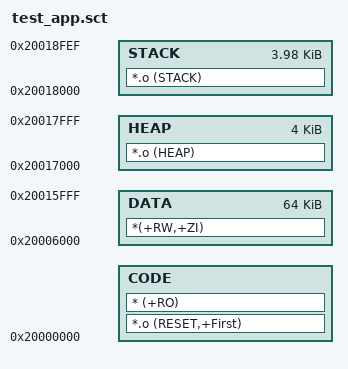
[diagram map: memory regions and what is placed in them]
; *************************************************************
; *** Scatter-Loading Description File generated by uVision ***
; *************************************************************

LOAD_REGION 0x20000000
{
	CODE 0x20000000
	{
		*.o (RESET,+First)
		* (+RO)	
	}
	DATA 0x20006000 0x10000
	{
		*(+RW,+ZI)
	}
	STACK 0x20018000 0xff0
	{
		*.o (STACK)	
	}
	HEAP 0x20017000 0x1000
	{
		*.o (HEAP)
	}
}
